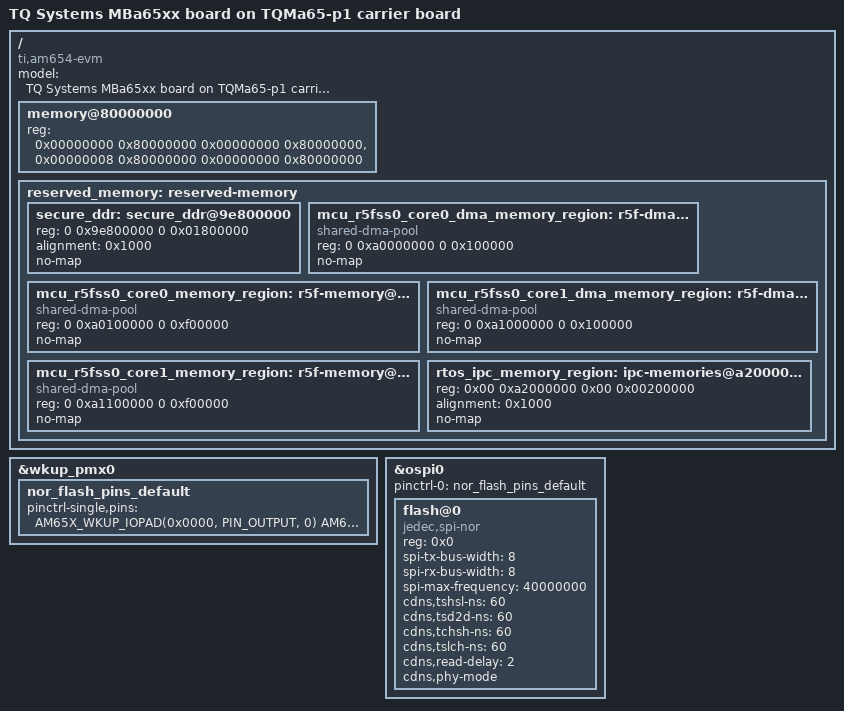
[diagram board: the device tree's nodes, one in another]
// SPDX-License-Identifier: GPL-2.0
/*
 * Copyright (C) 2016-2018 Texas Instruments Incorporated - http://www.ti.com/
 * Copyright (C) 2020 TQ Systems
 */

/dts-v1/;

#include "am654-mba65xx.dtsi"

/ {
	compatible =  "ti,am654-evm", "ti,am654";
	model = "TQ Systems MBa65xx board on TQMa65-p1 carrier board";

	memory@80000000 {
		device_type = "memory";
		/* 4G RAM */
		reg = <0x00000000 0x80000000 0x00000000 0x80000000>,
		      <0x00000008 0x80000000 0x00000000 0x80000000>;
	};

	reserved_memory: reserved-memory {
		#address-cells = <2>;
		#size-cells = <2>;
		ranges;

		secure_ddr: secure_ddr@9e800000 {
			reg = <0 0x9e800000 0 0x01800000>; /* for OP-TEE */
			alignment = <0x1000>;
			no-map;
		};

		mcu_r5fss0_core0_dma_memory_region: r5f-dma-memory@a0000000 {
			compatible = "shared-dma-pool";
			reg = <0 0xa0000000 0 0x100000>;
			no-map;
		};

		mcu_r5fss0_core0_memory_region: r5f-memory@a0100000 {
			compatible = "shared-dma-pool";
			reg = <0 0xa0100000 0 0xf00000>;
			no-map;
		};

		mcu_r5fss0_core1_dma_memory_region: r5f-dma-memory@a1000000 {
			compatible = "shared-dma-pool";
			reg = <0 0xa1000000 0 0x100000>;
			no-map;
		};

		mcu_r5fss0_core1_memory_region: r5f-memory@a1100000 {
			compatible = "shared-dma-pool";
			reg = <0 0xa1100000 0 0xf00000>;
			no-map;
		};

		rtos_ipc_memory_region: ipc-memories@a2000000 {
			reg = <0x00 0xa2000000 0x00 0x00200000>;
			alignment = <0x1000>;
			no-map;
		};
	};

};

&wkup_pmx0 {
	nor_flash_pins_default: nor_flash_pins_default {
		pinctrl-single,pins = <
			AM65X_WKUP_IOPAD(0x0000, PIN_OUTPUT, 0) /* (V1) MCU_OSPI0_CLK */
			AM65X_WKUP_IOPAD(0x002c, PIN_OUTPUT, 0) /* (R4) MCU_OSPI0_CSn0 */
			AM65X_WKUP_IOPAD(0x000c, PIN_INPUT, 0) /* (U4) MCU_OSPI0_D0 */
			AM65X_WKUP_IOPAD(0x0010, PIN_INPUT, 0) /* (U5) MCU_OSPI0_D1 */
			AM65X_WKUP_IOPAD(0x0014, PIN_INPUT, 0) /* (T2) MCU_OSPI0_D2 */
			AM65X_WKUP_IOPAD(0x0018, PIN_INPUT, 0) /* (T3) MCU_OSPI0_D3 */
			AM65X_WKUP_IOPAD(0x001c, PIN_INPUT, 0) /* (T4) MCU_OSPI0_D4 */
			AM65X_WKUP_IOPAD(0x0020, PIN_INPUT, 0) /* (T5) MCU_OSPI0_D5 */
			AM65X_WKUP_IOPAD(0x0024, PIN_INPUT, 0) /* (R2) MCU_OSPI0_D6 */
			AM65X_WKUP_IOPAD(0x0028, PIN_INPUT, 0) /* (R3) MCU_OSPI0_D7 */
			AM65X_WKUP_IOPAD(0x0008, PIN_INPUT, 0) /* (U2) MCU_OSPI0_DQS */
		>;
	};
};

&ospi0 {
	pinctrl-names = "default";
	pinctrl-0 = <&nor_flash_pins_default>;

	flash@0{
		compatible = "jedec,spi-nor";
		reg = <0x0>;
		spi-tx-bus-width = <8>;
		spi-rx-bus-width = <8>;
		spi-max-frequency = <40000000>;
		cdns,tshsl-ns = <60>;
		cdns,tsd2d-ns = <60>;
		cdns,tchsh-ns = <60>;
		cdns,tslch-ns = <60>;
		cdns,read-delay = <2>;
		cdns,phy-mode;
		#address-cells = <1>;
		#size-cells = <1>;
	};
};
